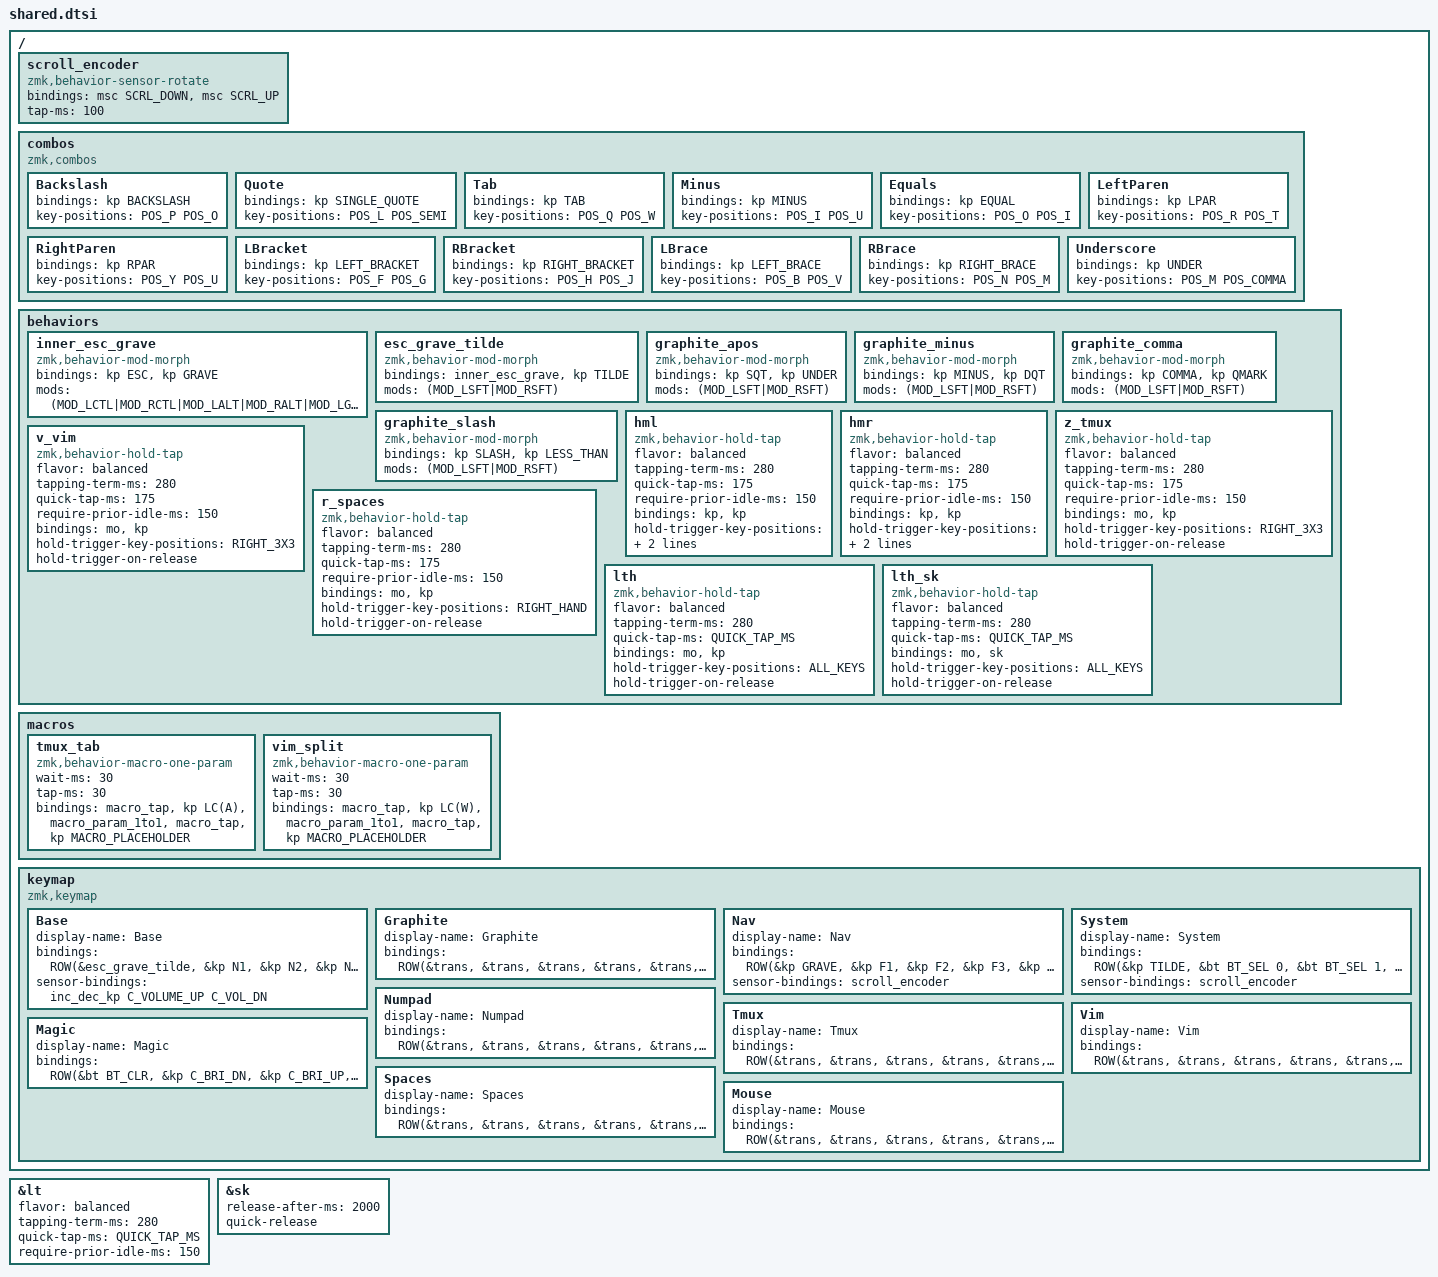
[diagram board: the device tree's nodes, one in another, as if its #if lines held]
/*
 * Shared keymap: behaviors, macros, combos, and layers.
 *
 * Included AFTER a positions file (positions_sofle.dtsi or positions_go60.dtsi)
 * which defines ROW/THUMB macros, POS_* constants, and position groups.
 */

#include <behaviors.dtsi>
#include <dt-bindings/zmk/bt.h>
#include <dt-bindings/zmk/keys.h>
#include <dt-bindings/zmk/outputs.h>
#include <dt-bindings/zmk/pointing.h>
#include <dt-bindings/zmk/rgb.h>

#define QUICK_TAP_MS 175

&lt {
    flavor = "balanced";
    tapping-term-ms = <280>;
    quick-tap-ms = <QUICK_TAP_MS>;
    require-prior-idle-ms = <150>;
};

&sk {
    release-after-ms = <2000>;
    quick-release;
};

/ {
#ifdef HAS_ENCODER
    scroll_encoder: scroll_encoder {
        compatible = "zmk,behavior-sensor-rotate";
        #sensor-binding-cells = <0>;
        bindings = <&msc SCRL_DOWN>, <&msc SCRL_UP>;
        tap-ms = <100>;
    };
#endif

    combos {
        compatible = "zmk,combos";

        Backslash {
            bindings = <&kp BACKSLASH>;
            key-positions = <POS_P POS_O>;
        };

        Quote {
            bindings = <&kp SINGLE_QUOTE>;
            key-positions = <POS_L POS_SEMI>;
        };

        Tab {
            bindings = <&kp TAB>;
            key-positions = <POS_Q POS_W>;
        };

        Minus {
            bindings = <&kp MINUS>;
            key-positions = <POS_I POS_U>;
        };

        Equals {
            bindings = <&kp EQUAL>;
            key-positions = <POS_O POS_I>;
        };

        LeftParen {
            bindings = <&kp LPAR>;
            key-positions = <POS_R POS_T>;
        };

        RightParen {
            bindings = <&kp RPAR>;
            key-positions = <POS_Y POS_U>;
        };

        LBracket {
            bindings = <&kp LEFT_BRACKET>;
            key-positions = <POS_F POS_G>;
        };

        RBracket {
            bindings = <&kp RIGHT_BRACKET>;
            key-positions = <POS_H POS_J>;
        };

        LBrace {
            bindings = <&kp LEFT_BRACE>;
            key-positions = <POS_B POS_V>;
        };

        RBrace {
            bindings = <&kp RIGHT_BRACE>;
            key-positions = <POS_N POS_M>;
        };

        Underscore {
            bindings = <&kp UNDER>;
            key-positions = <POS_M POS_COMMA>;
        };
    };

    behaviors {
        /* Custom Esc/Grave/Tilde behavior */

        inner_esc_grave: inner_esc_grave {
            compatible = "zmk,behavior-mod-morph";
            #binding-cells = <0>;
            bindings = <&kp ESC>, <&kp GRAVE>;
            mods = <(MOD_LCTL|MOD_RCTL|MOD_LALT|MOD_RALT|MOD_LGUI|MOD_RGUI)>;
        };

        esc_grave_tilde: esc_grave_tilde {
            compatible = "zmk,behavior-mod-morph";
            #binding-cells = <0>;
            bindings = <&inner_esc_grave>, <&kp TILDE>;
            mods = <(MOD_LSFT|MOD_RSFT)>;
        };

        /* Graphite mod-morph behaviors */

        graphite_apos: graphite_apos {
            compatible = "zmk,behavior-mod-morph";
            #binding-cells = <0>;
            bindings = <&kp SQT>, <&kp UNDER>;
            mods = <(MOD_LSFT|MOD_RSFT)>;
        };

        graphite_minus: graphite_minus {
            compatible = "zmk,behavior-mod-morph";
            #binding-cells = <0>;
            bindings = <&kp MINUS>, <&kp DQT>;
            mods = <(MOD_LSFT|MOD_RSFT)>;
        };

        graphite_comma: graphite_comma {
            compatible = "zmk,behavior-mod-morph";
            #binding-cells = <0>;
            bindings = <&kp COMMA>, <&kp QMARK>;
            mods = <(MOD_LSFT|MOD_RSFT)>;
        };

        graphite_slash: graphite_slash {
            compatible = "zmk,behavior-mod-morph";
            #binding-cells = <0>;
            bindings = <&kp SLASH>, <&kp LESS_THAN>;
            mods = <(MOD_LSFT|MOD_RSFT)>;
        };

        /* Left-hand HRMs */

        hml: hml {
            compatible = "zmk,behavior-hold-tap";
            #binding-cells = <2>;
            flavor = "balanced";
            tapping-term-ms = <280>;
            quick-tap-ms = <175>;
            require-prior-idle-ms = <150>;
            bindings = <&kp>, <&kp>;
            hold-trigger-key-positions = <RIGHT_HAND THUMB_KEYS>;
            hold-trigger-on-release;
        };

        /* Right-hand HRMs */

        hmr: hmr {
            compatible = "zmk,behavior-hold-tap";
            #binding-cells = <2>;
            flavor = "balanced";
            tapping-term-ms = <280>;
            quick-tap-ms = <175>;
            require-prior-idle-ms = <150>;
            bindings = <&kp>, <&kp>;
            hold-trigger-key-positions = <LEFT_HAND THUMB_KEYS>;
            hold-trigger-on-release;
        };

        z_tmux: z_tmux {
            compatible = "zmk,behavior-hold-tap";
            #binding-cells = <2>;
            flavor = "balanced";
            tapping-term-ms = <280>;
            quick-tap-ms = <175>;
            require-prior-idle-ms = <150>;
            bindings = <&mo>, <&kp>;
            hold-trigger-key-positions = <RIGHT_3X3>;
            hold-trigger-on-release;
        };

        v_vim: v_vim {
            compatible = "zmk,behavior-hold-tap";
            #binding-cells = <2>;
            flavor = "balanced";
            tapping-term-ms = <280>;
            quick-tap-ms = <175>;
            require-prior-idle-ms = <150>;
            bindings = <&mo>, <&kp>;
            hold-trigger-key-positions = <RIGHT_3X3>;
            hold-trigger-on-release;
        };

        r_spaces: r_spaces {
            compatible = "zmk,behavior-hold-tap";
            #binding-cells = <2>;
            flavor = "balanced";
            tapping-term-ms = <280>;
            quick-tap-ms = <175>;
            require-prior-idle-ms = <150>;
            bindings = <&mo>, <&kp>;
            hold-trigger-key-positions = <RIGHT_HAND>;
            hold-trigger-on-release;
        };

        lth: lth {
            compatible = "zmk,behavior-hold-tap";
            #binding-cells = <2>;
            flavor = "balanced";
            tapping-term-ms = <280>;
            quick-tap-ms = <QUICK_TAP_MS>;
            bindings = <&mo>, <&kp>;
            hold-trigger-key-positions = <ALL_KEYS>;
            hold-trigger-on-release;
        };

        lth_sk: lth_sk {
            compatible = "zmk,behavior-hold-tap";
            #binding-cells = <2>;
            flavor = "balanced";
            tapping-term-ms = <280>;
            quick-tap-ms = <QUICK_TAP_MS>;
            bindings = <&mo>, <&sk>;
            hold-trigger-key-positions = <ALL_KEYS>;
            hold-trigger-on-release;
        };
    };

    macros {
        tmux_tab: tmux_tab {
            compatible = "zmk,behavior-macro-one-param";
            #binding-cells = <1>;
            wait-ms = <30>;
            tap-ms = <30>;
            bindings =
                <&macro_tap &kp LC(A)>
                , <&macro_param_1to1>
                , <&macro_tap &kp MACRO_PLACEHOLDER>;
        };

        vim_split: vim_split {
            compatible = "zmk,behavior-macro-one-param";
            #binding-cells = <1>;
            wait-ms = <30>;
            tap-ms = <30>;
            bindings =
                <&macro_tap &kp LC(W)>
                , <&macro_param_1to1>
                , <&macro_tap &kp MACRO_PLACEHOLDER>;
        };
    };

    /* ── Layers ───────────────────────────────────────────────────
     *
     * ROW params:  l6  l5  l4  l3  l2  l1  enc  r1  r2  r3  r4  r5  r6
     *              ─── LH C6→C1 (outer→inner) ──  ── RH C1→C6 (inner→outer) ──
     *
     * THUMB params (14, union of both boards):
     *   enc        Sofle encoder press (Sofle only)
     *   lc4r5      LH C4R5  left bottom outer
     *   lc3r5      LH C3R5  left bottom mid
     *   lc2r5      LH C2R5  left bottom inner
     *   lht3       LH T3    left thumb outer
     *   lht2       LH T2    left thumb mid
     *   lht1       LH T1    left thumb inner (Go60 only)
     *   mid        Sofle middle key (Sofle only)
     *   rht1       RH T1    right thumb inner (Go60 only)
     *   rht2       RH T2    right thumb mid
     *   rht3       RH T3    right thumb outer
     *   rc2r5      RH C2R5  right bottom inner
     *   rc3r5      RH C3R5  right bottom mid
     *   rc4r5      RH C4R5  right bottom outer
     */

    keymap {
        compatible = "zmk,keymap";

        Base {
            display-name = "Base";
            bindings = <
ROW(&esc_grave_tilde, &kp N1,        &kp N2,           &kp N3,           &kp N4,         &kp N5,
    &kp UP_ARROW,
    &kp N6,           &kp N7,        &kp N8,           &kp N9,           &kp N0,         &kp BACKSPACE)
ROW(&kp TAB,          &kp Q,         &kp W,            &kp E,            &r_spaces 8 R,  &kp T,
    &kp DOWN_ARROW,
    &kp Y,            &kp U,         &kp I,            &kp O,            &kp P,          &kp BSLH)
ROW(&kp GLOBE,        &hml LCTRL A,  &hml LEFT_ALT S,  &hml LEFT_GUI D,  &hml LSHIFT F,  &kp G,
    &kp LEFT_ARROW,
    &kp H,            &hmr RSHIFT J, &hmr RIGHT_GUI K, &hmr RIGHT_ALT L, &hmr RCTRL SEMICOLON, &kp APOS)
ROW(&kp LSHFT,        &z_tmux 5 Z,   &kp X,            &kp C,            &v_vim 6 V,     &kp B,
    &kp RIGHT_ARROW,
    &kp N,            &kp M,         &kp COMMA,        &kp DOT,          &kp SLASH,      &kp RIGHT_SHIFT)
THUMB(&kp C_MUTE,                                              /* enc       (Sofle only) */
      &kp LCTRL,     &kp LEFT_ALT,  &kp LEFT_GUI,             /* LH C4R5 C3R5 C2R5     */
      &lth 2 SPACE,  &lth 4 ENTER,                             /* LH T3 T2              */
      &kp ENTER,                                                /* LH T1    (Go60 only)  */
      &kp ENTER,                                                /* mid      (Sofle only) */
      &kp ESC,                                                   /* RH T1    (Go60 only)  */
      &lth_sk 7 RSHIFT, &lth 3 SPACE,                           /* RH T2 T3              */
      &kp BACKSPACE, &kp C_VOLUME_DOWN, &kp C_VOLUME_UP)       /* RH C2R5 C3R5 C4R5     */
            >;

#ifdef HAS_ENCODER
            sensor-bindings = <&inc_dec_kp C_VOLUME_UP C_VOL_DN>;
#endif
        };

        Graphite {
            display-name = "Graphite";
            bindings = <
ROW(&trans,  &trans,           &trans,           &trans,            &trans,            &trans,
    &trans,
    &trans,  &trans,           &trans,            &trans,            &trans,            &trans)
ROW(&trans,  &kp B,            &kp L,            &kp D,             &r_spaces 8 W,     &kp Z,
    &trans,
    &graphite_apos,  &kp F,   &kp O,            &kp U,             &kp J,             &trans)
ROW(&trans,  &hml LCTRL N,     &hml LEFT_ALT R,  &hml LEFT_GUI T,   &hml LSHIFT S,     &trans,
    &trans,
    &kp Y,   &hmr RSHIFT H,   &hmr RIGHT_GUI A, &hmr RIGHT_ALT E,  &hmr RCTRL I,      &graphite_comma)
ROW(&trans,  &z_tmux 5 Q,      &trans,           &kp M,             &v_vim 6 C,        &kp V,
    &trans,
    &kp K,   &kp P,            &kp DOT,          &graphite_minus,   &graphite_slash,   &trans)
THUMB(&trans,
      &trans, &trans, &trans,
      &trans, &trans,
      &trans,
      &trans,
      &trans,
      &trans, &trans,
      &trans, &trans, &trans)
            >;
        };

        Nav {
            display-name = "Nav";
            bindings = <
ROW(&kp GRAVE,  &kp F1,       &kp F2,      &kp F3,       &kp F4,       &kp F5,
    &mmv MOVE_UP,
    &kp F6,     &kp F7,       &kp F8,       &kp F9,       &kp F10,      &trans)
ROW(&trans,     &kp GRAVE,    &mkp LCLK,    &mkp MCLK,    &kp LG(R),    &mkp MB4,
    &mmv MOVE_DOWN,
    &kp PG_UP,  &kp HOME,     &kp UP,       &kp END,      &kp MINUS,    &kp EQUAL)
ROW(&trans,     &kp TILDE,    &trans,        &trans,       &trans,        &mkp MB5,
    &mmv MOVE_LEFT,
    &kp PG_DN,  &kp LEFT,     &kp DOWN,     &kp RIGHT,    &kp LEFT_BRACKET, &kp RIGHT_BRACKET)
ROW(&trans,     &kp LG(Z),    &kp LG(X),    &kp LG(C),    &kp LG(V),    &trans,
    &mmv MOVE_RIGHT,
    &trans,     &trans,        &kp INSERT,   &kp F11,      &kp F12,      &trans)
THUMB(&kp C_MUTE,
      &trans, &trans, &trans,
      &trans, &trans,
      &trans,
      &mkp LCLK,
      &trans,
      &trans, &kp ENTER,
      &trans, &trans, &trans)
            >;

#ifdef HAS_ENCODER
            sensor-bindings = <&scroll_encoder>;
#endif
        };

        System {
            display-name = "System";
            bindings = <
ROW(&kp TILDE,  &bt BT_SEL 0,  &bt BT_SEL 1,  &bt BT_SEL 2,   &bt BT_SEL 3,    &bt BT_SEL 4,
    &mmv MOVE_UP,
    &kp F6,     &kp F7,        &kp F8,         &kp F9,          &kp F10,          &trans)
ROW(&trans,     &to 0,          &to 1,          &trans,          &trans,            &trans,
    &mmv MOVE_DOWN,
    &trans,     &trans,         &trans,          &trans,          &trans,            &trans)
ROW(&trans,     &out OUT_USB,   &out OUT_BLE,   &bt BT_CLR,      &bt BT_CLR_ALL,   &trans,
    &mmv MOVE_LEFT,
    &trans,     &trans,         &trans,          &trans,          &kp LBRC,          &kp RBRC)
ROW(&trans,     &sys_reset,     &trans,         &bootloader,      &trans,            &trans,
    &mmv MOVE_RIGHT,
    &trans,     &trans,         &sys_reset,      &soft_off,       &bootloader,       &trans)
THUMB(&trans,
      &trans, &trans, &trans,
      &trans, &trans,
      &trans,
      &mkp LCLK,
      &trans,
      &trans, &trans,
      &trans, &trans, &trans)
            >;

#ifdef HAS_ENCODER
            sensor-bindings = <&scroll_encoder>;
#endif
        };

        Numpad {
            display-name = "Numpad";
            bindings = <
ROW(&trans,  &trans,            &trans,            &trans,             &trans,             &trans,
    &trans,
    &trans,  &trans,            &trans,             &trans,             &trans,             &trans)
ROW(&trans,  &kp N1,            &kp N2,            &kp N3,             &kp N4,             &kp N5,
    &trans,
    &kp N6,  &kp N7,            &kp N8,             &kp N9,             &kp N0,             &trans)
ROW(&trans,  &rgb_ug RGB_BRI,   &rgb_ug RGB_BRD,   &trans,             &trans,             &trans,
    &trans,
    &trans,  &kp N4,            &kp N5,             &kp N6,             &kp MINUS,          &trans)
ROW(&trans,  &rgb_ug RGB_OFF,   &rgb_ug RGB_ON,    &rgb_ug RGB_EFF,    &rgb_ug RGB_EFR,    &rgb_ug RGB_SPI,
    &trans,
    &trans,  &kp N1,            &kp N2,             &kp N3,             &kp LS(PLUS),       &trans)
THUMB(&trans,
      &trans, &trans, &trans,
      &trans, &trans,
      &trans,
      &trans,
      &trans,
      &trans, &trans,
      &kp N0, &kp N0, &trans)
            >;
        };

        Tmux {
            display-name = "Tmux";
            bindings = <
ROW(&trans, &trans, &trans, &trans, &trans, &trans,    &trans,    &trans, &trans,        &trans,        &trans,        &trans, &trans)
ROW(&trans, &trans, &trans, &trans, &trans, &trans,    &trans,    &trans, &tmux_tab N7,  &tmux_tab N8,  &tmux_tab N9,  &trans, &trans)
ROW(&trans, &trans, &trans, &trans, &trans, &trans,    &trans,    &trans, &tmux_tab N4,  &tmux_tab N5,  &tmux_tab N6,  &trans, &trans)
ROW(&trans, &trans, &trans, &trans, &trans, &trans,    &trans,    &trans, &tmux_tab N1,  &tmux_tab N2,  &tmux_tab N3,  &trans, &trans)
THUMB(&trans,
      &trans, &trans, &trans,
      &trans, &trans,
      &trans,
      &trans,
      &trans,
      &trans, &trans,
      &tmux_tab N0, &trans, &trans)
            >;
        };

        Vim {
            display-name = "Vim";
            bindings = <
ROW(&trans, &trans, &trans, &trans, &trans, &trans,    &trans,    &trans, &trans,       &trans,       &trans,       &trans, &trans)
ROW(&trans, &trans, &trans, &trans, &trans, &trans,    &trans,    &trans, &trans,       &vim_split K, &trans,       &trans, &trans)
ROW(&trans, &trans, &trans, &trans, &trans, &trans,    &trans,    &trans, &vim_split H, &vim_split J, &vim_split L, &trans, &trans)
ROW(&trans, &trans, &trans, &trans, &trans, &trans,    &trans,    &trans, &trans,       &trans,       &trans,       &trans, &trans)
THUMB(&trans,
      &trans, &trans, &trans,
      &trans, &trans,
      &trans,
      &trans,
      &trans,
      &trans, &trans,
      &trans, &trans, &trans)
            >;
        };

        Magic {
            display-name = "Magic";
            bindings = <
ROW(&bt BT_CLR,  &kp C_BRI_DN,       &kp C_BRI_UP,       &kp C_PREV,          &kp C_NEXT,          &kp C_PP,
    &none,
    &kp C_MUTE,  &kp C_VOL_DN,       &kp C_VOL_UP,        &none,               &none,               &bt BT_CLR_ALL)
ROW(&bootloader, &rgb_ug RGB_SPI,     &rgb_ug RGB_SAI,     &rgb_ug RGB_HUI,     &rgb_ug RGB_BRI,     &rgb_ug RGB_TOG,
    &none,
    &none,       &none,               &none,                &none,               &none,               &bootloader)
ROW(&sys_reset,  &rgb_ug RGB_SPD,     &rgb_ug RGB_SAD,     &rgb_ug RGB_HUD,     &rgb_ug RGB_BRD,     &rgb_ug RGB_EFF,
    &none,
    &none,       &none,               &none,                &none,               &none,               &sys_reset)
ROW(&none,       &none,               &bt BT_SEL 0,        &bt BT_SEL 1,        &bt BT_SEL 2,        &bt BT_SEL 3,
    &none,
    &none,       &none,               &none,                &none,               &none,               &none)
THUMB(&none,
      &out OUT_USB, &none, &none,
      &none, &none,
      &none,
      &none,
      &none,
      &none, &none,
      &none, &none, &none)
            >;
        };

        Spaces {
            display-name = "Spaces";
            bindings = <
ROW(&trans, &trans, &trans, &trans, &trans, &trans,
    &trans,
    &trans,         &trans,        &kp LC(UP),    &trans,         &trans,   &trans)
ROW(&trans, &trans, &trans, &trans, &trans, &trans,
    &trans,
    &kp LG(GRAVE),  &kp LC(LEFT),  &kp LC(DOWN),  &kp LC(RIGHT),  &kp F11,  &trans)
ROW(&trans, &trans, &trans, &trans, &trans, &trans,
    &trans,
    &trans,         &trans,        &trans,        &trans,         &trans,   &trans)
ROW(&trans, &trans, &trans, &trans, &trans, &trans,
    &trans,
    &trans,         &trans,        &trans,        &trans,         &trans,   &trans)
THUMB(&trans,
      &trans, &trans, &trans,
      &trans, &trans,
      &trans,
      &trans,
      &trans,
      &trans, &trans,
      &trans, &trans, &trans)
            >;
        };

        /* Layer 9 — activated automatically by the Go60 trackpads via
         * &zip_temp_layer (see go60_lh.keymap / go60_rh.keymap), and
         * dropped MOUSE_LAYER_MS after the last pointer event.  Only the
         * right thumb keys are overridden: T1 = left click, T2 = right
         * click.  Not reachable on the Sofle (no pointing device).
         */
        Mouse {
            display-name = "Mouse";
            bindings = <
ROW(&trans, &trans, &trans, &trans, &trans, &trans,    &trans,    &trans, &trans, &trans, &trans, &trans, &trans)
ROW(&trans, &trans, &trans, &trans, &trans, &trans,    &trans,    &trans, &trans, &trans, &trans, &trans, &trans)
ROW(&trans, &trans, &trans, &trans, &trans, &trans,    &trans,    &trans, &trans, &trans, &trans, &trans, &trans)
ROW(&trans, &trans, &trans, &trans, &trans, &trans,    &trans,    &trans, &trans, &trans, &trans, &trans, &trans)
THUMB(&trans,
      &trans, &trans, &trans,
      &trans, &trans,
      &trans,
      &trans,
      &mkp LCLK,                                                 /* RH T1 */
      &mkp RCLK, &trans,                                         /* RH T2 T3 */
      &trans, &trans, &trans)
            >;
        };
    };
};
